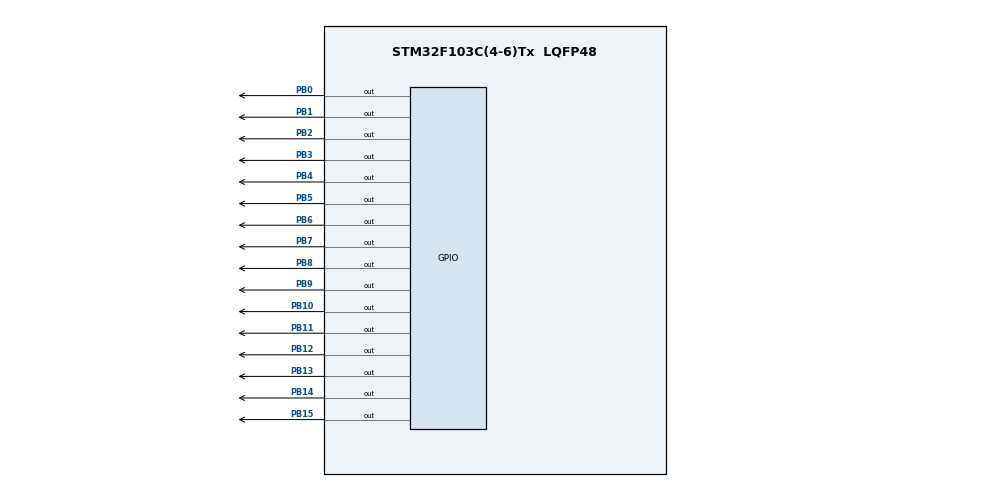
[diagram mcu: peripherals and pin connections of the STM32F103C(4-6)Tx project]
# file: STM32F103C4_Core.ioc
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Mcu.Family=STM32F1
Mcu.Name=STM32F103C(4-6)Tx
Mcu.Package=LQFP48
NVIC.PriorityGroup=NVIC_PRIORITYGROUP_4
PB0.Signal=GPIO_Output
PB1.Signal=GPIO_Output
PB10.Signal=GPIO_Output
PB11.Signal=GPIO_Output
PB12.Signal=GPIO_Output
PB13.Signal=GPIO_Output
PB14.Signal=GPIO_Output
PB15.Signal=GPIO_Output
PB2.Signal=GPIO_Output
PB3.Signal=GPIO_Output
PB4.Signal=GPIO_Output
PB5.Signal=GPIO_Output
PB6.Signal=GPIO_Output
PB7.Signal=GPIO_Output
PB8.Signal=GPIO_Output
PB9.Signal=GPIO_Output
ProjectManager.HeapSize=0x200
ProjectManager.StackSize=0x400
ProjectManager.TargetToolchain=MDK-ARM V4
RCC.APB1Freq_Value=8000000
RCC.APB2Freq_Value=8000000
VP_SYS_VS_ND.Mode=No_Debug
board=custom

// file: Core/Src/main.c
/* USER CODE BEGIN Header */
/**
  ******************************************************************************
  * @file           : main.c
  * @brief          : Main program body
  ******************************************************************************
  * @attention
  *
  * Copyright (c) 2022 STMicroelectronics.
  * All rights reserved.
  *
  * This software is licensed under terms that can be found in the LICENSE file
  * in the root directory of this software component.
  * If no LICENSE file comes with this software, it is provided AS-IS.
  *
  ******************************************************************************
  */
/* USER CODE END Header */
#include "main.h"

void SystemClock_Config(void);
static void MX_GPIO_Init(void);

int main(void)
{
  /* USER CODE BEGIN 1 */
	int time = 0;
	int hour = 0;
	int minute = 0;
	int second = 0;
  /* USER CODE END 1 */

  /* MCU Configuration--------------------------------------------------------*/

  /* Reset of all peripherals, Initializes the Flash interface and the Systick. */
  HAL_Init();

  /* Configure the system clock */
  SystemClock_Config();

  /* USER CODE BEGIN SysInit */
	__HAL_AFIO_REMAP_SWJ_DISABLE();
  /* USER CODE END SysInit */

  /* Initialize all configured peripherals */
  MX_GPIO_Init();

  /* Infinite loop */
  while (1)
  {

    /* USER CODE BEGIN 3 */

		HAL_GPIO_TogglePin(GPIOC, GPIO_PIN_13);
		HAL_GPIO_WritePin(GPIOA, GPIO_PIN_All, GPIO_PIN_RESET);

		second = time % 3600 % 60;
		minute = (time - second) % 3600 / 60;
		hour = (time - minute - second) / 3600 % 24;

		#define DEBUG

		#ifdef RELEASE_2_2
			HAL_GPIO_WritePin(GPIOA, (hour / 10)<<0, GPIO_PIN_SET);
			HAL_GPIO_WritePin(GPIOA, (hour % 10)<<4, GPIO_PIN_SET);

			HAL_GPIO_WritePin(GPIOA, (minute / 10)<<8, GPIO_PIN_SET);
			HAL_GPIO_WritePin(GPIOA, (minute % 10)<<12, GPIO_PIN_SET);
		#endif

		#ifdef RELEASE_2_2_2
			HAL_GPIO_WritePin(GPIOA, (hour / 10)<<0, GPIO_PIN_SET);
			HAL_GPIO_WritePin(GPIOA, (hour % 10)<<4, GPIO_PIN_SET);

			HAL_GPIO_WritePin(GPIOA, (minute / 10)<<8, GPIO_PIN_SET);
			HAL_GPIO_WritePin(GPIOA, (minute % 10)<<12, GPIO_PIN_SET);

			HAL_GPIO_WritePin(GPIOB, (second / 10)<<4, GPIO_PIN_SET);
			HAL_GPIO_WritePin(GPIOB, (second % 10)<<8, GPIO_PIN_SET);
		#endif

		#ifdef DEBUG
			HAL_GPIO_WritePin(GPIOA, (minute / 10)<<0, GPIO_PIN_SET);
			HAL_GPIO_WritePin(GPIOA, (minute % 10)<<4, GPIO_PIN_SET);

			HAL_GPIO_WritePin(GPIOA, (second / 10)<<8, GPIO_PIN_SET);
			HAL_GPIO_WritePin(GPIOA, (second % 10)<<12, GPIO_PIN_SET);
		#endif

		HAL_Delay(1000);

		if (time == 24 * 60 * 60) {
			time = 0;
		}
		else {
			time++;
		}
   }
  /* USER CODE END 3 */
}

void SystemClock_Config(void)
{
  RCC_OscInitTypeDef RCC_OscInitStruct = {0};
  RCC_ClkInitTypeDef RCC_ClkInitStruct = {0};

  /** Initializes the RCC Oscillators according to the specified parameters
  * in the RCC_OscInitTypeDef structure.
  */
  RCC_OscInitStruct.OscillatorType = RCC_OSCILLATORTYPE_HSI;
  RCC_OscInitStruct.HSIState = RCC_HSI_ON;
  RCC_OscInitStruct.HSICalibrationValue = RCC_HSICALIBRATION_DEFAULT;
  RCC_OscInitStruct.PLL.PLLState = RCC_PLL_NONE;
  if (HAL_RCC_OscConfig(&RCC_OscInitStruct) != HAL_OK)
  {
    Error_Handler();
  }
  /** Initializes the CPU, AHB and APB buses clocks
  */
  RCC_ClkInitStruct.ClockType = RCC_CLOCKTYPE_HCLK|RCC_CLOCKTYPE_SYSCLK
                              |RCC_CLOCKTYPE_PCLK1|RCC_CLOCKTYPE_PCLK2;
  RCC_ClkInitStruct.SYSCLKSource = RCC_SYSCLKSOURCE_HSI;
  RCC_ClkInitStruct.AHBCLKDivider = RCC_SYSCLK_DIV1;
  RCC_ClkInitStruct.APB1CLKDivider = RCC_HCLK_DIV1;
  RCC_ClkInitStruct.APB2CLKDivider = RCC_HCLK_DIV1;

  if (HAL_RCC_ClockConfig(&RCC_ClkInitStruct, FLASH_LATENCY_0) != HAL_OK)
  {
    Error_Handler();
  }
}

static void MX_GPIO_Init(void)
{
  GPIO_InitTypeDef GPIO_InitStruct = {0};

  /* GPIO Ports Clock Enable */
  __HAL_RCC_GPIOA_CLK_ENABLE();
	__HAL_RCC_GPIOC_CLK_ENABLE();

  /*Configure GPIO pin Output Level */
  HAL_GPIO_WritePin(GPIOA, GPIO_PIN_All, GPIO_PIN_RESET);

  /*Configure GPIO pins : PA_All */
  GPIO_InitStruct.Pin = GPIO_PIN_All;
  GPIO_InitStruct.Mode = GPIO_MODE_OUTPUT_PP;
  GPIO_InitStruct.Pull = GPIO_NOPULL;
  GPIO_InitStruct.Speed = GPIO_SPEED_FREQ_LOW;
  HAL_GPIO_Init(GPIOA, &GPIO_InitStruct);

	GPIO_InitStruct.Pin = 0x00FF;
	GPIO_InitStruct.Mode = GPIO_MODE_OUTPUT_PP;
	HAL_GPIO_Init(GPIOB, &GPIO_InitStruct);

	GPIO_InitStruct.Pin = 0xFF00;
	GPIO_InitStruct.Mode = GPIO_MODE_INPUT;
	GPIO_InitStruct.Pull = GPIO_PULLUP;
	HAL_GPIO_Init(GPIOB, &GPIO_InitStruct);

	GPIO_InitStruct.Pin = GPIO_PIN_13;
	HAL_GPIO_Init(GPIOC, &GPIO_InitStruct);

}

void Error_Handler(void)
{
  __disable_irq();
  while (1)
  {
  }
}
